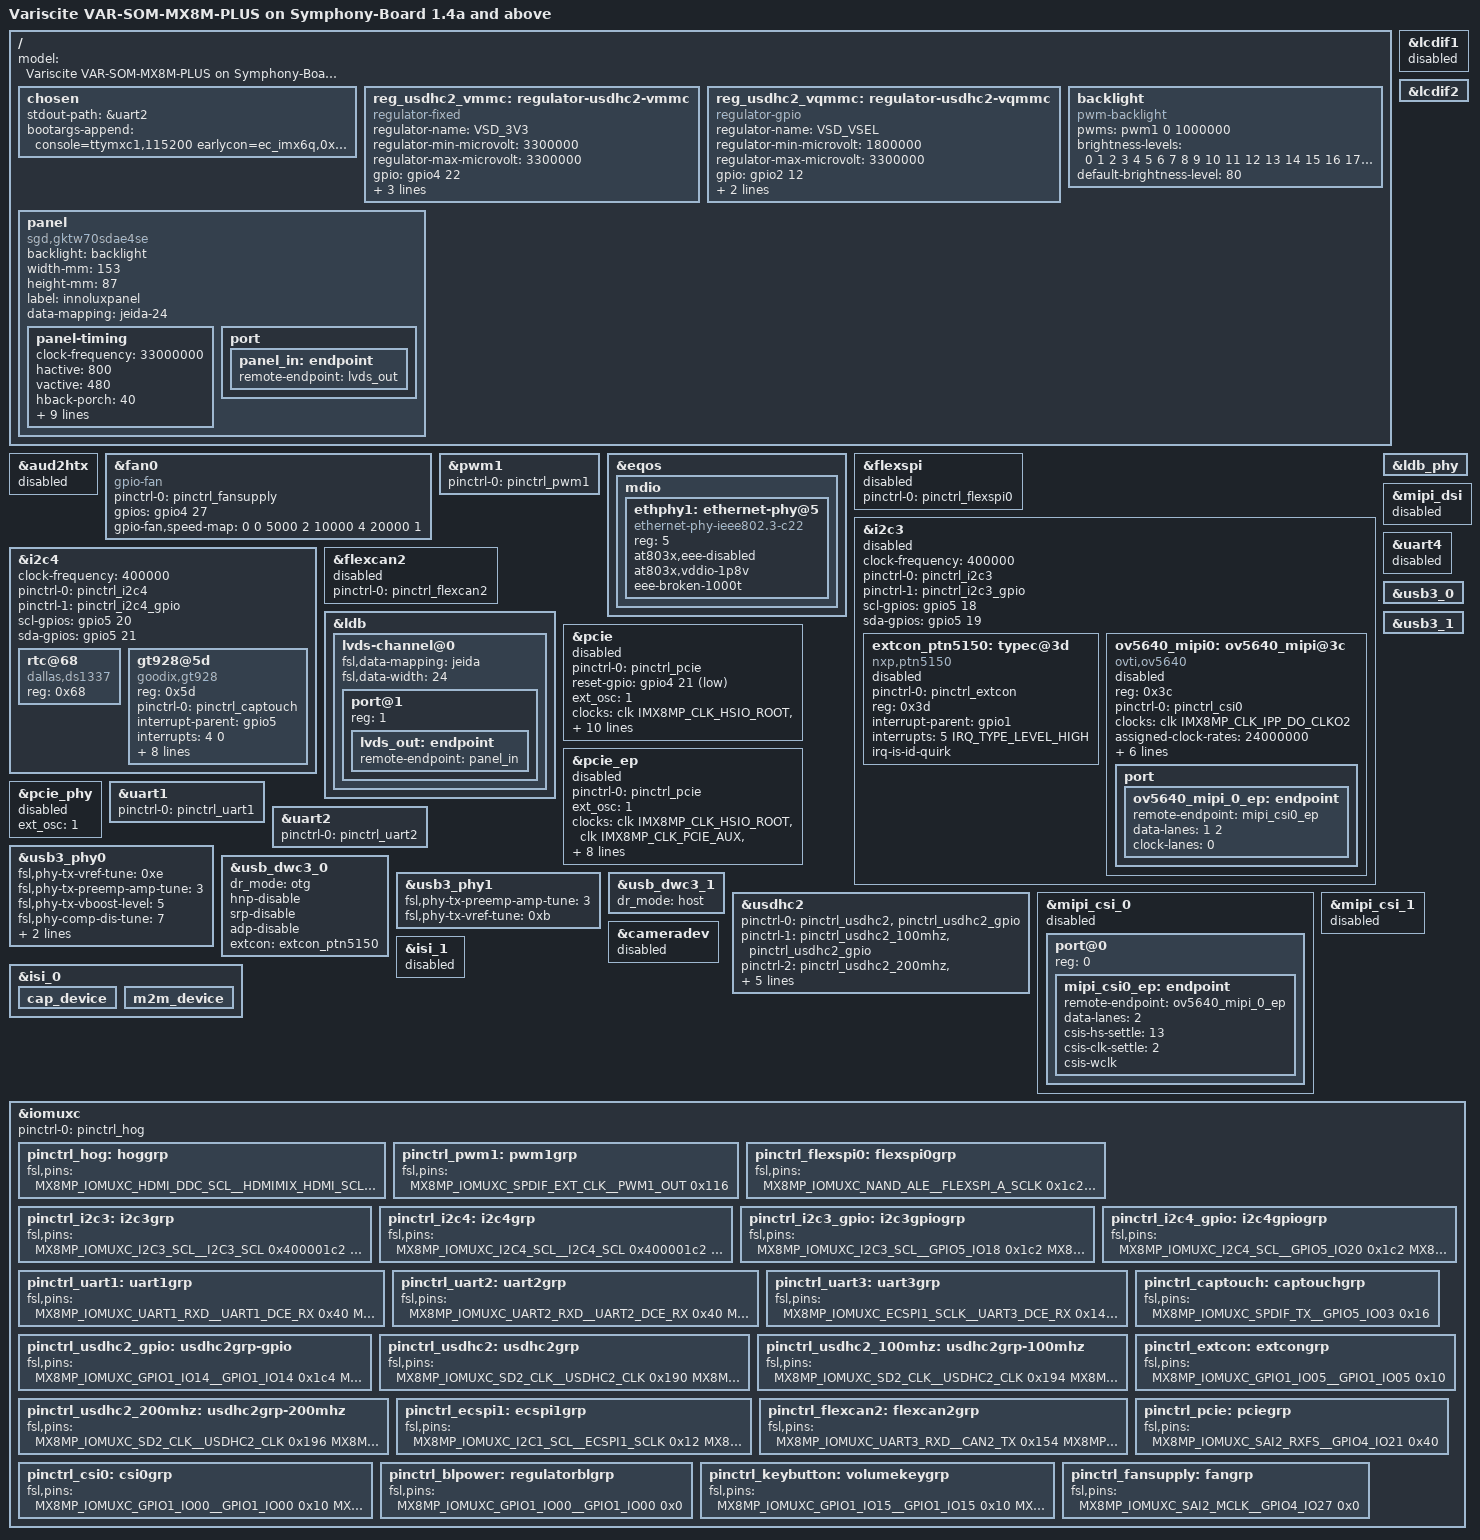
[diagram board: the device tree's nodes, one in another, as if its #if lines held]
// SPDX-License-Identifier: (GPL-2.0+ OR MIT)
/*
 * Copyright 2019 NXP
 * Copyright 2020-2021 Variscite Ltd.
 */

#include "imx8mp-var-som.dtsi"

//#define DEV_KIT 1
#define DEBUG_SERIAL 1

/ {
	model = "Variscite VAR-SOM-MX8M-PLUS on Symphony-Board 1.4a and above";

	chosen {
#ifdef DEBUG_SERIAL
		stdout-path = &uart2;
		bootargs-append = "console=ttymxc1,115200 earlycon=ec_imx6q,0x30890000,115200 androidboot.console=ttymxc1  androidboot.primary_display=imx-drm androidboot.board=varsommx8mp androidboot.bt_sdio=/sys/bus/mmc/devices/mmc0:0001/mmc0:0001:1/device androidboot.bt_sdio_id=0x4339 androidboot.bt_uart=/dev/ttymxc2 androidboot.wificountrycode=US";
#else
		bootargs-append = "console=null androidboot.console=null androidboot.primary_display=imx-drm androidboot.board=varsommx8mp androidboot.bt_sdio=/sys/bus/mmc/devices/mmc0:0001/mmc0:0001:1/device androidboot.bt_sdio_id=0x4339 androidboot.bt_uart=/dev/ttymxc2 androidboot.wificountrycode=US";
#endif
	};

	
	reg_usdhc2_vmmc: regulator-usdhc2-vmmc {
		compatible = "regulator-fixed";
		regulator-name = "VSD_3V3";
		regulator-min-microvolt = <3300000>;
		regulator-max-microvolt = <3300000>;
		gpio = <&gpio4 22 GPIO_ACTIVE_HIGH>;
		enable-active-high;
		startup-delay-us = <100>;
		off-on-delay-us = <12000>;
	};

	reg_usdhc2_vqmmc: regulator-usdhc2-vqmmc {
		compatible = "regulator-gpio";
		regulator-name = "VSD_VSEL";
		regulator-min-microvolt = <1800000>;
		regulator-max-microvolt = <3300000>;
		gpio = <&gpio2 12 GPIO_ACTIVE_HIGH>;
		gpios-states = <1>;
		states = <3300000 0
			  1800000 1>;
	};

	backlight: backlight {
		compatible = "pwm-backlight";
		pwms = <&pwm1 0 1000000>;
		status = "okay";

		brightness-levels = < 0  1  2  3  4  5  6  7  8  9
				     10 11 12 13 14 15 16 17 18 19
				     20 21 22 23 24 25 26 27 28 29
				     30 31 32 33 34 35 36 37 38 39
				     40 41 42 43 44 45 46 47 48 49
				     50 51 52 53 54 55 56 57 58 59
				     60 61 62 63 64 65 66 67 68 69
				     70 71 72 73 74 75 76 77 78 79
				     80 81 82 83 84 85 86 87 88 89
				     90 91 92 93 94 95 96 97 98 99
				    100>;
		default-brightness-level = <80>;
#if DEV_KIT
#else
        power-supply = <&vdd_bl_reg>;
#endif

	};

/*
	fan: gpio-fan {
		compatible = "gpio-fan";
		gpio-fan,speed-map = <0 0 8600 1>;
		gpios = <&gpio3 5 GPIO_ACTIVE_HIGH>;
		#cooling-cells = <2>;
		pinctrl-names = "default";
		pinctrl-0 = <&pinctrl_fanio>;
		interrupt-parent = <&gpio5>;
		interrupts = <12 IRQ_TYPE_EDGE_RISING>;
		status = "okay";
	};*/

#if DEV_KIT
#else
	gpio-keys {
		compatible = "gpio-keys";
		status = "okay";
		pinctrl-names = "default";
		pinctrl-0 = <&pinctrl_keybutton>;


		//Volume +
		volumep {
			label = "VolumeUP";
			gpios = <&gpio1 15 GPIO_ACTIVE_LOW>;
			linux,code = <KEY_VOLUMEUP>;
			//interrupt-parent = <&gpio1>;
			//interrupts = <15 IRQ_TYPE_EDGE_FALLING>;
			//wakeup-source;
		};

		// Volume -
		volumed {
			label = "VolumeDOWN";
			gpios = <&gpio4 17 GPIO_ACTIVE_LOW>;
			linux,code = <KEY_VOLUMEDOWN>;
			//interrupt-parent = <&gpio4>;
			//interrupts = <17 IRQ_TYPE_EDGE_FALLING>;
		 	//wakeup-source;
		};

		poweroff {
			label = "PowerOFF";
			gpios = <&gpio5 28 GPIO_ACTIVE_LOW>;
			linux,code = <KEY_POWER>;
			//interrupt-parent = <&gpio5>;
			//interrupts = <28 IRQ_TYPE_EDGE_FALLING>;
		 	wakeup-source;
		};
	};
#endif

	panel {
		compatible = "sgd,gktw70sdae4se", "panel-lvds";
		backlight = <&backlight>;
#if DEV_KIT
		width-mm = <153>;
		height-mm = <87>;
#else
		width-mm = <430>;
		height-mm = <254>;
#endif
		label = "innoluxpanel";
#if DEV_KIT
		data-mapping = "jeida-24";
#else
		data-mapping = "vesa-24";
#endif
		status = "okay";

		panel-timing {
#if DEV_KIT
			clock-frequency = <33000000>;
			hactive = <800>;
			vactive = <480>;
			hback-porch = <40>;
			hfront-porch = <40>;
			vback-porch = <29>;
			vfront-porch = <13>;
			hsync-len = <48>;
			vsync-len = <3>;
			hsync-active = <0>;
			vsync-active = <0>;
#else
			clock-frequency = <148500000>; /* Fc x 2*/
			hactive = <1920>; /* Thd x 2 */
			vactive = <1080>; /* Tvd */
			/* hback-porch + hfront-porch + hsync-len = (Th - Thd) x 2 = 280 */
			hback-porch = <90>;
			hfront-porch = <90>;
			hsync-len = <100>;
			/* vback-porch + vfront-porch + vsync-len = Tv - Tvd = 45 */
			vback-porch = <15>;
			vfront-porch = <15>;
			vsync-len = <15>;
#endif

			/* Uses DE or not (1 = DE active high, 0 = DE active low)
				Not specified = not used */
			de-active = <1>;
			/* Rising or falling edge? 0 = rising */
			pixelclk-active = <0>;
		};

		port {
			panel_in: endpoint {
				remote-endpoint = <&lvds_out>;
			};
		};
	};


#if DEV_KIT
#else
    vdd_bl_reg: regulator-bl {
		compatible = "regulator-fixed";
		pinctrl-names = "default";
		pinctrl-0 = <&pinctrl_blpower>;
		// Prerequisite to appear in terminal log when enabled / disabled
		regulator-name = "vdd_backlight";
		regulator-min-microvolt = <3300000>;
		regulator-max-microvolt = <3300000>;
		// Changing next line to enable-gpios causes BL to be ON at boot and never go off
		//gpio = <&gpio4 20 GPIO_ACTIVE_LOW>;
		gpio = <&gpio1 00 GPIO_ACTIVE_LOW>;
		// Regulator must have the REGULATOR_CHANGE_STATUS property
		// See https://elixir.bootlin.com/linux/v5.10.52/source/drivers/regulator/core.c
		// REMOVE THIS REQUIRED BY GPIO DRIVER enable-active-high; else "GPIO handle specifies active low - ignored"
		status = "okay";
	};
#endif

#if GPIO_FAN
#else
    vdd_pwmfan_reg: regulator-pwn {
		compatible = "regulator-fixed";
		pinctrl-names = "default";
		pinctrl-0 = <&pinctrl_fansupply>;
		// Prerequisite to appear in terminal log when enabled / disabled
		regulator-name = "vdd_pwm_fan";
		regulator-min-microvolt = <3300000>;
		regulator-max-microvolt = <3300000>;
		gpio = <&gpio4 27 GPIO_ACTIVE_HIGH>;
		enable-active-high;
		status = "disabled";
	};
#endif
};

&aud2htx {
	status = "disabled";
};
#if GPIO_FAN
&fan0 {
	compatible = "gpio-fan";
	pinctrl-names = "default";
	pinctrl-0 = <&pinctrl_fansupply>;
	gpios = <&gpio4 27 GPIO_ACTIVE_HIGH>;
 	gpio-fan,speed-map = <0 0 5000 2 10000 4 20000 1>;
	status = "okay";
};

#else
&fan0 {
	pwms = <&pwm2 0 1000 0>;
	cooling-levels = <0 255>;
	pulses-per-revolution = <2>;
	fan-supply = <&vdd_pwmfan_reg>;
	interrupt-parent = <&gpio1>;
	interrupts = <9 IRQ_TYPE_EDGE_RISING>;
	status = "okay";
};
#endif

&pwm1 {
	pinctrl-names = "default";
	pinctrl-0 = <&pinctrl_pwm1>;
	status = "okay";
};

/* Setup Gpio Fan */
#if GPIO_FAN
#else
&pwm2 {
	pinctrl-names = "default";
	pinctrl-0 = <&pinctrl_pwm2>;
	status = "okay";
};
#endif

&eqos {
	mdio {
		ethphy1: ethernet-phy@5 {
			compatible = "ethernet-phy-ieee802.3-c22";
			reg = <5>;
			at803x,eee-disabled;
			at803x,vddio-1p8v;
			eee-broken-1000t;
		};
	};
};


&flexspi {
	pinctrl-names = "default";
	pinctrl-0 = <&pinctrl_flexspi0>;
	status = "disabled";
};


&i2c3 {
	clock-frequency = <400000>;
	pinctrl-names = "default", "gpio";
	pinctrl-0 = <&pinctrl_i2c3>;
	pinctrl-1 = <&pinctrl_i2c3_gpio>;
	scl-gpios = <&gpio5 18 GPIO_ACTIVE_HIGH>;
	sda-gpios = <&gpio5 19 GPIO_ACTIVE_HIGH>;
	status = "disabled";
	/* USB Type-C Controller */
	extcon_ptn5150: typec@3d {
		compatible = "nxp,ptn5150";
		pinctrl-names = "default";
		pinctrl-0 = <&pinctrl_extcon>;
		reg = <0x3d>;
		interrupt-parent = <&gpio1>;
		interrupts = <5 IRQ_TYPE_LEVEL_HIGH>;
		irq-is-id-quirk;
		status = "disabled";
	};

	ov5640_mipi0: ov5640_mipi@3c {
		compatible = "ovti,ov5640";
		reg = <0x3c>;
		pinctrl-names = "default";
		pinctrl-0 = <&pinctrl_csi0>;
		clocks = <&clk IMX8MP_CLK_IPP_DO_CLKO2>;
		clock-names = "xclk";
/* Disabled CLKO2, since DART-MX8MP camera expansion board uses
 * its own oscillator. Enable CLK02 if your desing requres it
 */
#if 0
		assigned-clocks = <&clk IMX8MP_CLK_IPP_DO_CLKO2>;
		assigned-clock-parents = <&clk IMX8MP_CLK_24M>;
#endif
		assigned-clock-rates = <24000000>;
		csi_id = <0>;
		powerdown-gpios = <&gpio1 8 GPIO_ACTIVE_HIGH>;
		reset-gpios = <&gpio1 0 GPIO_ACTIVE_LOW>;
		mclk = <24000000>;
		mclk_source = <0>;
		mipi_csi;
		status = "disabled";

		port {
			ov5640_mipi_0_ep: endpoint {
				remote-endpoint = <&mipi_csi0_ep>;
				data-lanes = <1 2>;
				clock-lanes = <0>;
			};
		};
	};
};


&i2c4 {
	clock-frequency = <400000>;
	pinctrl-names = "default", "gpio";
	pinctrl-0 = <&pinctrl_i2c4>;
	pinctrl-1 = <&pinctrl_i2c4_gpio>;
	scl-gpios = <&gpio5 20 GPIO_ACTIVE_HIGH>;
	sda-gpios = <&gpio5 21 GPIO_ACTIVE_HIGH>;
	status = "okay";

	/* DS1337 RTC module */
	rtc@68 {
		compatible = "dallas,ds1337";
		reg = <0x68>;
		status = "okay";
	};

	/* Capacitive touch controller */
	gt928@5d {
		status = "okay";
		compatible = "goodix,gt928";
		reg = <0x5d>; // 7 low bit only => 0101 1101 => 1011 101[0] => 0xBA
		pinctrl-names = "default";
		pinctrl-0 = <&pinctrl_captouch>;
		interrupt-parent = <&gpio5>;
		interrupts = <4 0>;
		irq-gpios = <&gpio5 4 0>;
		reset-gpios = <&gpio4 12 0>;
		touchscreen-size-x = <1920>; //horizontal resolution of touchscreen(in pixels)
		touchscreen-size-y = <1280>; //vertical resolution of touchscreen(in pixels)
		/*touchscreen-inverted-x;*/
		/*touchscreen-inverted-y;*/
		goodix,driver-send-cfg = <1>;
		goodix,auto-update-cfg = <0>;
		goodix,cfg-group0 = [
			42 80 07 00 05 0A 3D 00 01 08 28
			0F 50 32 03 05 00 00 00 00 00 00
			00 18 1A 1E 14 90 30 CC 34 36 82
			0A 00 00 00 01 03 1D 00 00 00 00
			00 03 00 00 00 00 00 27 46 94 D5
			02 07 00 00 04 93 29 00 89 2E 00
			80 34 00 78 3A 00 70 42 00 70 00
			00 00 00 00 00 00 00 00 00 00 00
			00 00 00 00 00 00 00 00 00 00 00
			00 00 00 00 00 00 00 00 00 00 00
			00 00 00 01 04 05 06 07 08 09 0C
			0D 0E 0F 10 11 14 15 16 17 18 19
			1A 1B 1C 1D 00 00 00 00 00 00 00
			02 04 06 07 08 0A 0C 0D 0E 0F 10
			11 12 13 14 19 1B 1C 1E 1F 20 21
			22 23 24 25 26 27 28 29 2A 00 00
			00 00 00 00 00 00 00 00 EC 01
			];			
	};
};


&flexcan2 {
	pinctrl-names = "default";
	pinctrl-0 = <&pinctrl_flexcan2>;
	status = "disabled";
};



/* MIPI-DSI */
&lcdif1 {
	status = "disabled";
};

/* LVDS */
&lcdif2 {
	status = "okay";
};

//change according to V2.2

&ldb {
	status = "okay";
#ifdef DEV_KIT
#else
	fsl,dual-channel;
#endif
	lvds-channel@0 {
#ifdef DEV_KIT
		fsl,data-mapping = "jeida";
#else
		fsl,data-mapping = "spwg";
#endif
		// RGB888 mode
		fsl,data-width = <24>;
		status = "okay";

		port@1 {
			reg = <1>;

			lvds_out: endpoint {
				remote-endpoint = <&panel_in>;
			};
		};
	};
};

&ldb_phy {
	status = "okay";
};

&mipi_dsi {
	status = "disabled";
};

&pcie {
	pinctrl-names = "default";
	pinctrl-0 = <&pinctrl_pcie>;
	reset-gpio = <&gpio4 21 GPIO_ACTIVE_LOW>;
	ext_osc = <1>;
	clocks = <&clk IMX8MP_CLK_HSIO_ROOT>,
		 <&clk IMX8MP_CLK_PCIE_AUX>,
		 <&clk IMX8MP_CLK_HSIO_AXI>,
		 <&clk IMX8MP_CLK_PCIE_ROOT>;
	clock-names = "pcie", "pcie_aux", "pcie_phy", "pcie_bus";
	assigned-clocks = <&clk IMX8MP_CLK_HSIO_AXI>,
			  <&clk IMX8MP_CLK_PCIE_AUX>;
	assigned-clock-rates = <500000000>, <10000000>;
	assigned-clock-parents = <&clk IMX8MP_SYS_PLL2_500M>,
				 <&clk IMX8MP_SYS_PLL2_50M>;
	l1ss-disabled;
	status = "disabled";
};

&pcie_ep {
	pinctrl-names = "default";
	pinctrl-0 = <&pinctrl_pcie>;
	ext_osc = <1>;
	clocks = <&clk IMX8MP_CLK_HSIO_ROOT>,
		 <&clk IMX8MP_CLK_PCIE_AUX>,
		 <&clk IMX8MP_CLK_HSIO_AXI>,
		 <&clk IMX8MP_CLK_PCIE_ROOT>;
	clock-names = "pcie", "pcie_aux", "pcie_phy", "pcie_bus";
	assigned-clocks = <&clk IMX8MP_CLK_HSIO_AXI>,
			  <&clk IMX8MP_CLK_PCIE_AUX>;
	assigned-clock-rates = <500000000>, <10000000>;
	assigned-clock-parents = <&clk IMX8MP_SYS_PLL2_500M>,
				 <&clk IMX8MP_SYS_PLL2_50M>;
	status = "disabled";
};

&pcie_phy {
	ext_osc = <1>;
	status = "disabled";
};

/* Header */
&uart1 {
	pinctrl-names = "default";
	pinctrl-0 = <&pinctrl_uart1>;
	status = "okay";
};

/* Console */
&uart2 {
	pinctrl-names = "default";
	pinctrl-0 = <&pinctrl_uart2>;
#ifdef DEBUG_SERIAL
	status = "okay";
#else
	status = "disabled";
#endif
};

/* Header */
&uart4 {
	pinctrl-names = "default";
	// pinctrl-0 = <&pinctrl_uart4>;
	status = "disabled";
};

&usb3_phy0 {
	fsl,phy-tx-vref-tune = <0xe>;
	fsl,phy-tx-preemp-amp-tune = <3>;
	fsl,phy-tx-vboost-level = <5>;
	fsl,phy-comp-dis-tune = <7>;
	fsl,pcs-tx-deemph-3p5db = <0x21>;
	fsl,phy-pcs-tx-swing-full = <0x7f>;
	status = "okay";
};

&usb3_0 {
	status = "okay";
};

&usb_dwc3_0 {
#ifdef DEV_KIT
	dr_mode = "otg";
	hnp-disable;
	srp-disable;
	adp-disable;
	extcon = <&extcon_ptn5150>;
#else
	dr_mode = "host";
#endif
	status = "okay";
};

&usb3_phy1 {
	fsl,phy-tx-preemp-amp-tune = <3>;
	fsl,phy-tx-vref-tune = <0xb>;
	status = "okay";
};

&usb3_1 {
	status = "okay";
};

&usb_dwc3_1 {
	dr_mode = "host";
	status = "okay";
};

&usdhc2 {
	pinctrl-names = "default", "state_100mhz", "state_200mhz";
	pinctrl-0 = <&pinctrl_usdhc2>, <&pinctrl_usdhc2_gpio>;
	pinctrl-1 = <&pinctrl_usdhc2_100mhz>, <&pinctrl_usdhc2_gpio>;
	pinctrl-2 = <&pinctrl_usdhc2_200mhz>, <&pinctrl_usdhc2_gpio>;
	cd-gpios = <&gpio1 14 GPIO_ACTIVE_LOW>;
	vmmc-supply = <&reg_usdhc2_vmmc>;
	vqmmc-supply = <&reg_usdhc2_vqmmc>;
	bus-width = <4>;
	status = "okay";
};

&mipi_csi_0 {
	#address-cells = <1>;
	#size-cells = <0>;
	status = "disabled";

	port@0 {
		reg = <0>;
		mipi_csi0_ep: endpoint {
			remote-endpoint = <&ov5640_mipi_0_ep>;
			data-lanes = <2>;
			csis-hs-settle = <13>;
			csis-clk-settle = <2>;
			csis-wclk;
		};
	};
};

&mipi_csi_1 {
	status = "disabled";
};

&cameradev {
	status = "disabled";
};

&isi_0 {
	status = "okay";

	cap_device {
		status = "okay";
	};

	m2m_device {
		status = "okay";
	};
};

&isi_1 {
	status = "disabled";
};

/*remove touch screen connected to gpio1
&ecspi1 {
	pinctrl-names = "default";
	pinctrl-0 = <&pinctrl_ecspi1>;
	cs-gpios = <&gpio5 17 GPIO_ACTIVE_LOW>;
	status = "okay";

	/* Resistive touch controller */
	/*
	ads7846@0 {
		compatible = "ti,ads7846";
		reg = <0>;
		pinctrl-names = "default";
		pinctrl-0 = <&pinctrl_restouch>;
		interrupt-parent = <&gpio1>;
		interrupts = <12 IRQ_TYPE_EDGE_FALLING>;
		spi-max-frequency = <1500000>;
		pendown-gpio = <&gpio1 12 GPIO_ACTIVE_LOW>;
		ti,x-min = /bits/ 16 <125>;
		ti,x-max = /bits/ 16 <4008>;
		ti,y-min = /bits/ 16 <282>;
		ti,y-max = /bits/ 16 <3864>;
		ti,x-plate-ohms = /bits/ 16 <180>;
		ti,pressure-max = /bits/ 16 <255>;
		ti,debounce-max = /bits/ 16 <10>;
		ti,debounce-tol = /bits/ 16 <3>;
		ti,debounce-rep = /bits/ 16 <1>;
		ti,settle-delay-usec = /bits/ 16 <150>;
		ti,keep-vref-on;
		wakeup-source;
		status = "okay";
	};
};
*/
/*
&ecspi2 {
	//pinctrl-names = "default";
	//pinctrl-0 = <&pinctrl_ecspi2>;
	//cs-gpios = <&gpio5 13 GPIO_ACTIVE_LOW>;
	status = "disable";

	spidev@0 {
		compatible = "var,spidev";
		reg = <0>;
		spi-max-frequency = <12000000>;
		status = "disable";
	};
};
*/

/*Remove unused gpio def
&gpio1 {
	cam_buf_hog {
		gpio-hog;
		gpios = <6 0>;
		output-low;
		line-name = "cam_buf";
	};
};
*/

&iomuxc {
	pinctrl-names = "default";
	pinctrl-0 = <&pinctrl_hog>;

	pinctrl_hog: hoggrp {
		fsl,pins = <
			MX8MP_IOMUXC_HDMI_DDC_SCL__HDMIMIX_HDMI_SCL			0x400001c2
			MX8MP_IOMUXC_HDMI_DDC_SDA__HDMIMIX_HDMI_SDA			0x400001c2
			MX8MP_IOMUXC_HDMI_HPD__HDMIMIX_HDMI_HPD				0x40000010
			MX8MP_IOMUXC_HDMI_CEC__HDMIMIX_HDMI_CEC				0x40000010
		>;
	};

	pinctrl_pwm1: pwm1grp {
		fsl,pins = <
			MX8MP_IOMUXC_SPDIF_EXT_CLK__PWM1_OUT				0x116
		>;
	};
#if GPIO_FAN
#else
	pinctrl_pwm2: pwm2grp {
		fsl,pins = <
			MX8MP_IOMUXC_GPIO1_IO09__PWM2_OUT					0x116
		>;
	};
#endif

	pinctrl_flexspi0: flexspi0grp {
		fsl,pins = <
			MX8MP_IOMUXC_NAND_ALE__FLEXSPI_A_SCLK				0x1c2
			MX8MP_IOMUXC_NAND_CE0_B__FLEXSPI_A_SS0_B			0x82
			MX8MP_IOMUXC_NAND_DATA00__FLEXSPI_A_DATA00			0x82
			MX8MP_IOMUXC_NAND_DATA01__FLEXSPI_A_DATA01			0x82
			MX8MP_IOMUXC_NAND_DATA02__FLEXSPI_A_DATA02			0x82
			MX8MP_IOMUXC_NAND_DATA03__FLEXSPI_A_DATA03			0x82
		>;
	};

	pinctrl_i2c3: i2c3grp {
		fsl,pins = <
			MX8MP_IOMUXC_I2C3_SCL__I2C3_SCL					0x400001c2
			MX8MP_IOMUXC_I2C3_SDA__I2C3_SDA					0x400001c2
		>;
	};

	pinctrl_i2c4: i2c4grp {
		fsl,pins = <
			MX8MP_IOMUXC_I2C4_SCL__I2C4_SCL					0x400001c2
			MX8MP_IOMUXC_I2C4_SDA__I2C4_SDA					0x400001c2
		>;
	};

	pinctrl_i2c3_gpio: i2c3gpiogrp {
		fsl,pins = <
			MX8MP_IOMUXC_I2C3_SCL__GPIO5_IO18				0x1c2
			MX8MP_IOMUXC_I2C3_SDA__GPIO5_IO19				0x1c2
		>;
	};

	pinctrl_i2c4_gpio: i2c4gpiogrp {
		fsl,pins = <
			MX8MP_IOMUXC_I2C4_SCL__GPIO5_IO20				0x1c2
			MX8MP_IOMUXC_I2C4_SDA__GPIO5_IO21				0x1c2
		>;
	};

	pinctrl_uart1: uart1grp {
		fsl,pins = <
			MX8MP_IOMUXC_UART1_RXD__UART1_DCE_RX				0x40
			MX8MP_IOMUXC_UART1_TXD__UART1_DCE_TX				0x40
		>;
	};

	pinctrl_uart2: uart2grp {
		fsl,pins = <
			MX8MP_IOMUXC_UART2_RXD__UART2_DCE_RX				0x40
			MX8MP_IOMUXC_UART2_TXD__UART2_DCE_TX				0x40
		>;
	};

	pinctrl_uart3: uart3grp {
		fsl,pins = <
			MX8MP_IOMUXC_ECSPI1_SCLK__UART3_DCE_RX				0x140
			MX8MP_IOMUXC_ECSPI1_MOSI__UART3_DCE_TX				0x140
			MX8MP_IOMUXC_ECSPI1_MISO__UART3_DCE_CTS				0x140
			MX8MP_IOMUXC_ECSPI1_SS0__UART3_DCE_RTS				0x140
		>;
	};
/*
	pinctrl_uart4: uart4grp {
		fsl,pins = <
			MX8MP_IOMUXC_UART4_RXD__UART4_DCE_RX				0x40
			MX8MP_IOMUXC_UART4_TXD__UART4_DCE_TX				0x40
		>;
	};
*/
	pinctrl_usdhc2_gpio: usdhc2grp-gpio {
		fsl,pins = <
			MX8MP_IOMUXC_GPIO1_IO14__GPIO1_IO14 				0x1c4
			MX8MP_IOMUXC_SAI2_RXC__GPIO4_IO22				0x10
			MX8MP_IOMUXC_SD2_CD_B__GPIO2_IO12				0xc0
		>;
	};

	pinctrl_usdhc2: usdhc2grp {
		fsl,pins = <
			MX8MP_IOMUXC_SD2_CLK__USDHC2_CLK				0x190
			MX8MP_IOMUXC_SD2_CMD__USDHC2_CMD				0x1d0
			MX8MP_IOMUXC_SD2_DATA0__USDHC2_DATA0				0x1d0
			MX8MP_IOMUXC_SD2_DATA1__USDHC2_DATA1				0x1d0
			MX8MP_IOMUXC_SD2_DATA2__USDHC2_DATA2				0x1d0
			MX8MP_IOMUXC_SD2_DATA3__USDHC2_DATA3				0x1d0
		>;
	};

	pinctrl_usdhc2_100mhz: usdhc2grp-100mhz {
		fsl,pins = <
			MX8MP_IOMUXC_SD2_CLK__USDHC2_CLK				0x194
			MX8MP_IOMUXC_SD2_CMD__USDHC2_CMD				0x1d4
			MX8MP_IOMUXC_SD2_DATA0__USDHC2_DATA0				0x1d4
			MX8MP_IOMUXC_SD2_DATA1__USDHC2_DATA1				0x1d4
			MX8MP_IOMUXC_SD2_DATA2__USDHC2_DATA2				0x1d4
			MX8MP_IOMUXC_SD2_DATA3__USDHC2_DATA3				0x1d4
		>;
	};

	pinctrl_usdhc2_200mhz: usdhc2grp-200mhz {
		fsl,pins = <
			MX8MP_IOMUXC_SD2_CLK__USDHC2_CLK				0x196
			MX8MP_IOMUXC_SD2_CMD__USDHC2_CMD				0x1d6
			MX8MP_IOMUXC_SD2_DATA0__USDHC2_DATA0				0x1d6
			MX8MP_IOMUXC_SD2_DATA1__USDHC2_DATA1				0x1d6
			MX8MP_IOMUXC_SD2_DATA2__USDHC2_DATA2				0x1d6
			MX8MP_IOMUXC_SD2_DATA3__USDHC2_DATA3				0x1d6
		>;
	};

	pinctrl_ecspi1: ecspi1grp {
		fsl,pins = <
			MX8MP_IOMUXC_I2C1_SCL__ECSPI1_SCLK				0x12
			MX8MP_IOMUXC_I2C1_SDA__ECSPI1_MOSI				0x12
			MX8MP_IOMUXC_I2C2_SCL__ECSPI1_MISO 				0x12
			MX8MP_IOMUXC_I2C2_SDA__GPIO5_IO17				0x12
		>;
	};
/*
	pinctrl_ecspi2: ecspi12grp {
		fsl,pins = <
			MX8MP_IOMUXC_ECSPI2_SCLK__ECSPI2_SCLK				0x12
			MX8MP_IOMUXC_ECSPI2_MOSI__ECSPI2_MOSI				0x12
			MX8MP_IOMUXC_ECSPI2_MISO__ECSPI2_MISO 				0x12
			MX8MP_IOMUXC_ECSPI2_SS0__GPIO5_IO13				0x12
		>;
	};
*/

	pinctrl_captouch: captouchgrp {
		fsl,pins = <
			MX8MP_IOMUXC_SPDIF_TX__GPIO5_IO03 				0x16
		>;
	};
/*
	pinctrl_restouch: restouchgrp {
		fsl,pins = <
			MX8MP_IOMUXC_GPIO1_IO12__GPIO1_IO12				0xc0
		>;
	};
*/
	pinctrl_extcon: extcongrp {
		fsl,pins = <
			MX8MP_IOMUXC_GPIO1_IO05__GPIO1_IO05				0x10
		>;
	};

	pinctrl_flexcan2: flexcan2grp {
		fsl,pins = <
			MX8MP_IOMUXC_UART3_RXD__CAN2_TX					0x154
			MX8MP_IOMUXC_UART3_TXD__CAN2_RX					0x154
		>;
	};

	pinctrl_pcie: pciegrp {
		fsl,pins = <
			MX8MP_IOMUXC_SAI2_RXFS__GPIO4_IO21				0x40
		>;
	};

	pinctrl_csi0: csi0grp {
		fsl,pins = <
			MX8MP_IOMUXC_GPIO1_IO00__GPIO1_IO00				0x10
			MX8MP_IOMUXC_GPIO1_IO08__GPIO1_IO08				0x10
			>;
	};


    pinctrl_blpower: regulatorblgrp {
	 	fsl,pins = <
	 		 /*MX8MP_IOMUXC_SAI1_MCLK__GPIO4_IO20 				0x0   */
	 		 MX8MP_IOMUXC_GPIO1_IO00__GPIO1_IO00				0x0
	 	>;
	};

	//vol+
	pinctrl_keybutton: volumekeygrp {
		fsl,pins = <
			MX8MP_IOMUXC_GPIO1_IO15__GPIO1_IO15		0x10 /* VOL_P  0x16*/
	 		MX8MP_IOMUXC_SAI1_TXD5__GPIO4_IO17		0x10 /* VOL_M  0x16*/
	 		MX8MP_IOMUXC_UART4_RXD__GPIO5_IO28		0x10 /* POWER OFF  0x16*/
	 	>;
	};


	pinctrl_fansupply: fangrp {
	  	fsl,pins = <
	  		MX8MP_IOMUXC_SAI2_MCLK__GPIO4_IO27	0x0	/* FAN Supply Output  */
	  	>;
	};

};
